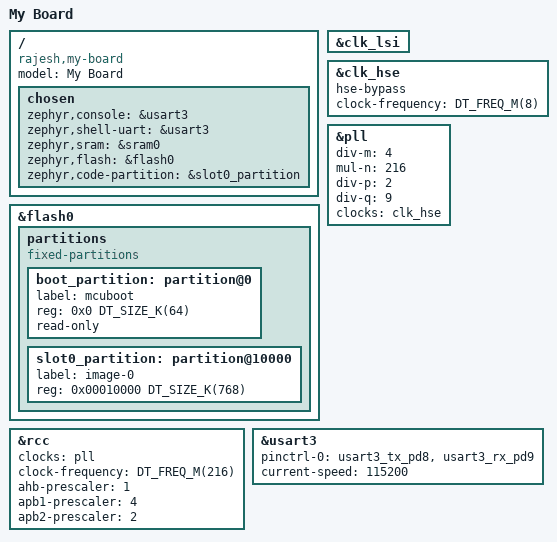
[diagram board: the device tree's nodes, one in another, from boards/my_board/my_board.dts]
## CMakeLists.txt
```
cmake_minimum_required(VERSION 3.20.0)

list(APPEND BOARD_ROOT ${CMAKE_CURRENT_SOURCE_DIR})
find_package(Zephyr REQUIRED)
project(my_zephyr_app)

target_sources(app PRIVATE src/main.cpp)
add_subdirectory(
    "${PROJECT_SOURCE_DIR}/../drivers/rajesh_driver"
    "${PROJECT_BINARY_DIR}/drivers/rajesh_driver"
)
```

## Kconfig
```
config APP_HEARTBEAT_PERIOD_MS
    int "App Heartbeat Period (ms)"
    default 500
    range 1 2000
    help
      This option sets the heartbeat period of the application.

source "Kconfig.zephyr"
rsource "../drivers/rajesh_driver/Kconfig"
```

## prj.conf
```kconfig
CONFIG_GPIO=y
CONFIG_LOG=y
CONFIG_SERIAL=y
CONFIG_SENSOR=y
CONFIG_RAJESH_DRIVER=y
```

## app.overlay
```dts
/{
	rajesh_driver0: rajesh_driver {
		compatible = "rajesh,driver";
		status = "okay";
	};
	

     aliases {
             my-led = &green_led;
     };
};
```

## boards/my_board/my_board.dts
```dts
/dts-v1/;

#include <st/f7/stm32f767Xi.dtsi>
#include <st/f7/stm32f767zitx-pinctrl.dtsi>
#include <zephyr/dt-bindings/input/input-event-codes.h>

/ {
    model = "My Board";
    compatible = "rajesh,my-board";
    chosen {
		zephyr,console = &usart3;
		zephyr,shell-uart = &usart3;
		zephyr,sram = &sram0;
		zephyr,flash = &flash0;
        zephyr,code-partition = &slot0_partition;
    };
};

&flash0 {
    partitions {
        compatible = "fixed-partitions";
        #address-cells = <1>;
        #size-cells = <1>;

        boot_partition: partition@0 {
            label = "mcuboot";
            reg = <0x0 DT_SIZE_K(64)>;
            read-only;
        };

        slot0_partition: partition@10000 {
            label = "image-0";
            reg = <0x00010000 DT_SIZE_K(768)>;
        };
    };
};

&clk_lsi {
	status = "okay";
};

&clk_hse {
	hse-bypass;
	clock-frequency = <DT_FREQ_M(8)>; /* STLink 8MHz clock */
	status = "okay";
};

&pll {
	div-m = <4>;
	mul-n = <216>;
	div-p = <2>;
	div-q = <9>;
	clocks = <&clk_hse>;
	status = "okay";
};

&rcc {
	clocks = <&pll>;
	clock-frequency = <DT_FREQ_M(216)>;
	ahb-prescaler = <1>;
	apb1-prescaler = <4>;
	apb2-prescaler = <2>;
};

&usart3 {
	pinctrl-0 = <&usart3_tx_pd8 &usart3_rx_pd9>;
	pinctrl-names = "default";
	current-speed = <115200>;
	status = "okay";
};
```

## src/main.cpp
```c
#include <zephyr/device.h>
#include <zephyr/drivers/sensor.h>
#include <zephyr/kernel.h>
#include <rajesh_driver.h>

static const struct device *const driver_dev = DEVICE_DT_GET(DT_NODELABEL(rajesh_driver0));

int main(void)
{
    if (!device_is_ready(driver_dev)) {
        return -ENODEV;
    }

    struct sensor_value value;

    int res = set_rajesh_data_counter(driver_dev, 100);
    if (res) {
        return res;
    }

    while (1) {
        res = sensor_sample_fetch(driver_dev);
        if (res) {
            printk("sensor_sample_fetch failed with response: %d\n", res);
            return res;
        }
        k_msleep(1000);

        res = sensor_channel_get(driver_dev, SENSOR_CHAN_ALL, &value);
        if (res) {
            printk("sensor_channel_get failed with response: %d\n", res);
            return res;
        }
        k_msleep(1000);

        res = increment_rajesh_data_counter(driver_dev);
        if (res) {
            return res;
        }

        uint32_t counter_value = get_rajesh_data_counter(driver_dev);
        printk("The counter value in Rajesh Driver is %u\n", (unsigned int)counter_value);

    }

    return 0;
}
```
